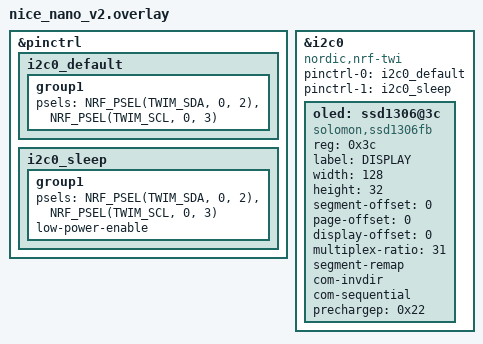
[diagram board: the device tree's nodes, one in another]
// CONFIGURATIE 1: P0.08/P0.11 (Standaard nRF52840)
&pinctrl {
    i2c0_default: i2c0_default {
        group1 {
            psels = <NRF_PSEL(TWIM_SDA, 0, 2)>,
                    <NRF_PSEL(TWIM_SCL, 0, 3)>;
        };
    };
    i2c0_sleep: i2c0_sleep {
        group1 {
           psels = <NRF_PSEL(TWIM_SDA, 0, 2)>,
                   <NRF_PSEL(TWIM_SCL, 0, 3)>;
            low-power-enable;
        };
    };
};

// ALS CONFIGURATIE 1 NIET WERKT, PROBEER CONFIGURATIE 2: P0.02/P0.03
// Vervang bovenstaande psels regels met:
//            psels = <NRF_PSEL(TWIM_SDA, 0, 2)>,
//                    <NRF_PSEL(TWIM_SCL, 0, 3)>;

// ALS CONFIGURATIE 2 NIET WERKT, PROBEER CONFIGURATIE 3: P0.17/P0.20  
// Vervang bovenstaande psels regels met:
//            psels = <NRF_PSEL(TWIM_SDA, 0, 17)>,
//                    <NRF_PSEL(TWIM_SCL, 0, 20)>;

&i2c0 {
    status = "okay";
    compatible = "nordic,nrf-twi";
    pinctrl-0 = <&i2c0_default>;
    pinctrl-1 = <&i2c0_sleep>;
    pinctrl-names = "default", "sleep";

    oled: ssd1306@3c {
        compatible = "solomon,ssd1306fb";
        reg = <0x3c>;
        label = "DISPLAY";
        width = <128>;
        height = <32>;
        segment-offset = <0>;
        page-offset = <0>;
        display-offset = <0>;
        multiplex-ratio = <31>;
        segment-remap;
        com-invdir;
        com-sequential;
        prechargep = <0x22>;
    };
};
